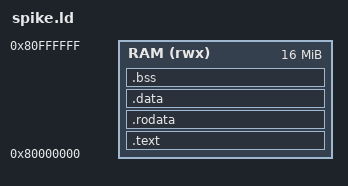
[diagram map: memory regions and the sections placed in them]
# linker script so spike will work

OUTPUT_ARCH("riscv")
ENTRY(_start)

MEMORY {
  RAM (rwx) : ORIGIN = 0x80000000, LENGTH = 16M
}

SECTIONS {
  .text : {
    KEEP(*(.text.start))
    *(.text*)
  } > RAM

  .rodata : {
    *(.rodata*)
  } > RAM

  .data : {
    *(.data*)
  } > RAM

  .bss : {
    *(.bss*)
    *(COMMON)
  } > RAM
}
